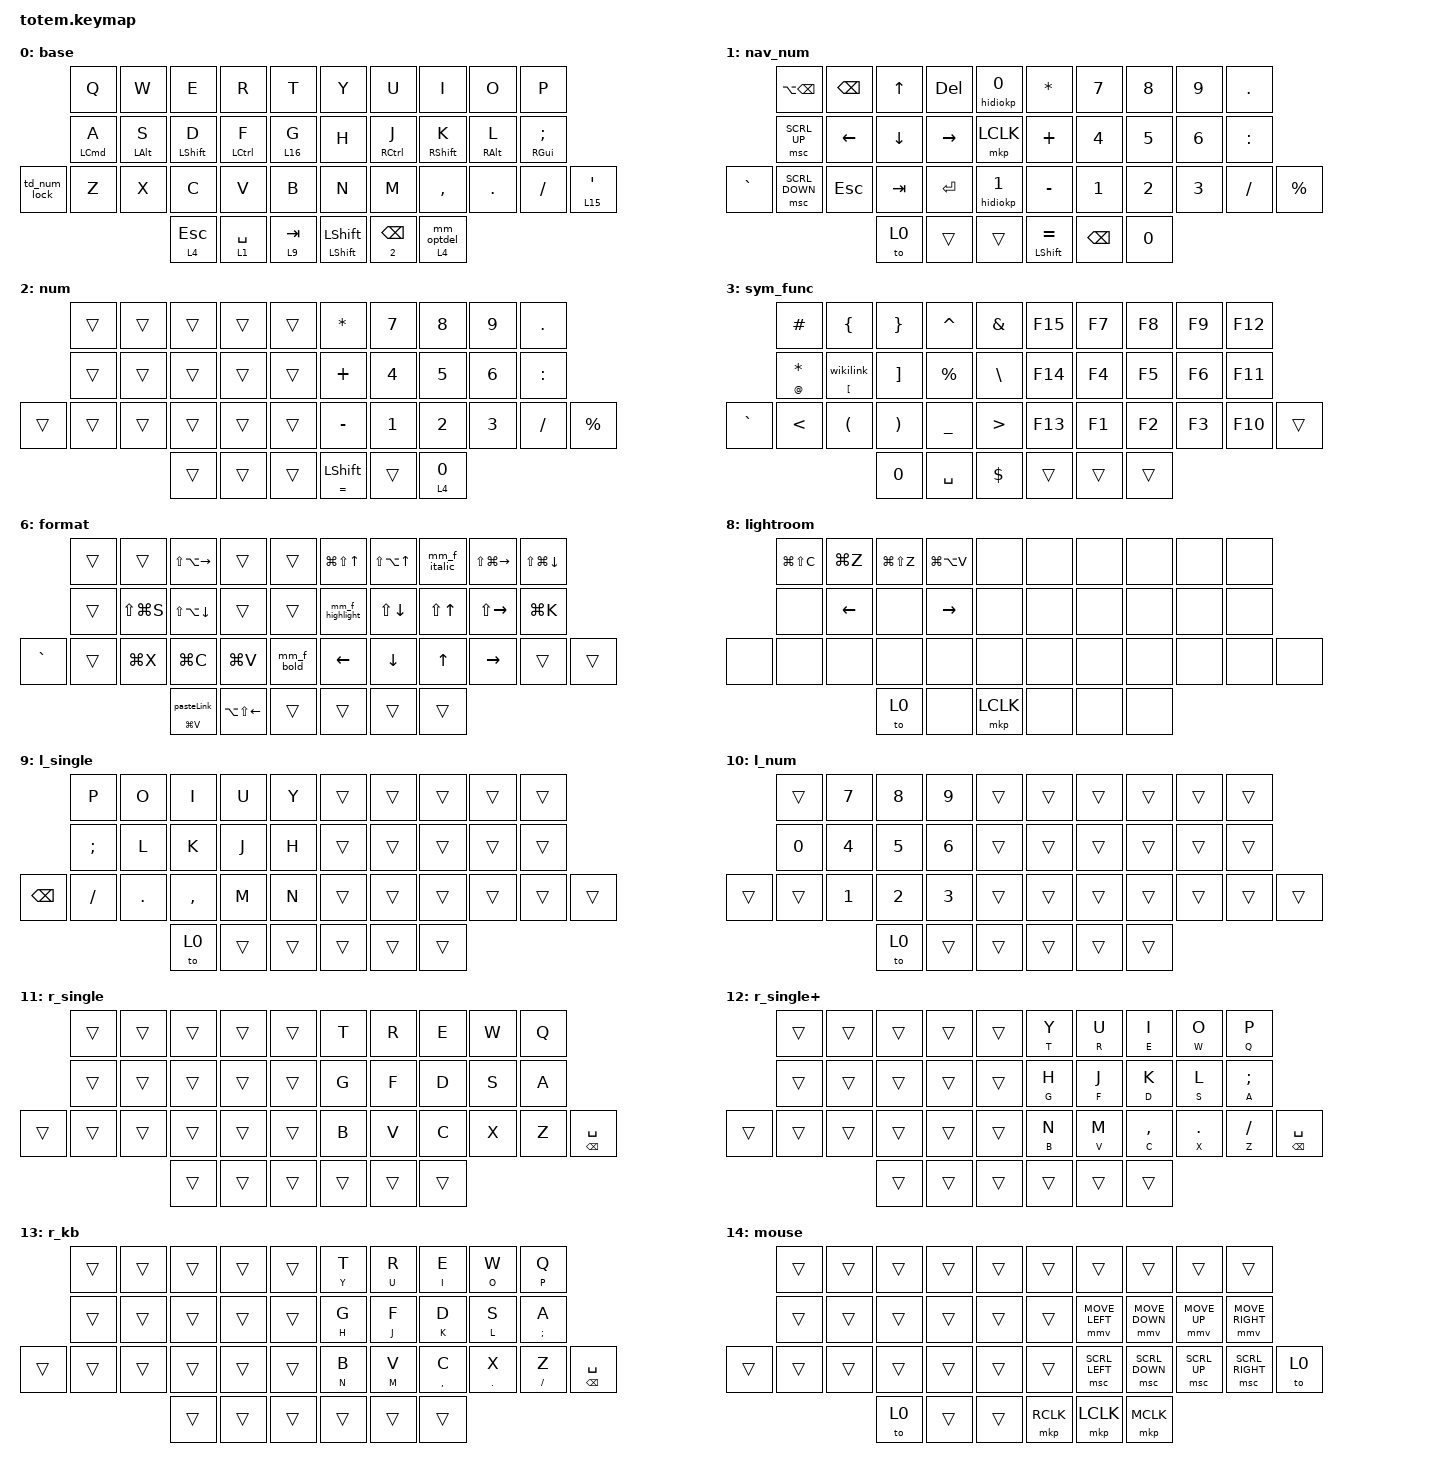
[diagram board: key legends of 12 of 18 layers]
//
//                                                        ▀▀▀▀▀     ▀▀▀▀▀          ▀▀█▀▀
//                                                        ▄▀▀▀▄  ▄  ▄▀▀▀▄  ▄  ▄▀▀▀▄  █  ▄▀▀▀▄
//                                                        █   █  █  █   █  █  █   █  █  █   █
//                                                         ▀▀▀   █   ▀▀▀   █   ▀▀▀   ▀   ▀▀▀
//                                                               █      ▄▄▄█▄▄▄    █   █  
//                                                               ▀      █  █  █     █▄█
//                                                             ▀▀▀▀▀    █  █  █      ▀
//                                                                      ▀  ▀  ▀
//
// ▄▄▄▄▄▄▄▄▄▄▄▄▄▄▄▄▄▄▄▄▄▄▄▄▄▄▄▄▄▄▄▄▄▄▄▄▄▄▄▄▄▄▄▄▄▄▄▄▄▄▄▄▄▄▄▄▄▄▄▄▄▄▄▄▄▄▄▄▄▄▄▄▄▄▄▄▄▄▄▄▄▄▄▄▄▄▄▄▄▄▄▄▄▄▄▄▄▄▄▄▄▄▄▄▄▄▄▄▄▄▄▄▄▄▄▄▄▄▄▄▄▄▄▄▄▄▄▄▄▄▄▄▄▄▄▄▄▄▄▄▄▄▄▄▄▄▄▄▄

#include <behaviors/num_word.dtsi>
#include <behaviors.dtsi>
#include <dt-bindings/zmk/bt.h>
#include <dt-bindings/zmk/keys.h>
#include <dt-bindings/zmk/pointing.h>

#define NUM 2
#define HID_IO_USAGE_FWD_TO_JOYSTICK 2

/ {
    /* Setup input-processor to intecept input and forward to new usage page  */

    zip_fwd_to_hid_io: zip_forward_fwd_to_hid_io {
        compatible = "zmk,input-processor-fwd-to-hid-io";
        #input-processor-cells = <0>;
        usage = <HID_IO_USAGE_FWD_TO_JOYSTICK>;
    };

    /* Setup joystick key press behavior and listener */
    /* listener shall forward to JOYSTICK usage page if CONFIG_ZMK_HID_IO_JOYSTICK is enabled */

    hidiokp: hid_io_key_press {
        compatible = "zmk,behavior-hid-io-key-press";
        #binding-cells = <1>;
    };

    hidiokp_ibl {
        compatible = "zmk,input-listener";
        device = <&hidiokp>;
        input-processors = <&zip_fwd_to_hid_io>;
    };

    combos {
        compatible = "zmk,combos";

        l-undo {
            bindings = <&kp LG(Z)>;
            key-positions = <12 23>;
            layers = <0 14>;
            timeout-ms = <25>;
            require-prior-idle-ms = <100>;
        };

        l-redo {
            bindings = <&kp LG(LS(Z))>;
            key-positions = <11 22>;
            layers = <0 14>;
            timeout-ms = <25>;
            require-prior-idle-ms = <100>;
        };

        l-paste {
            bindings = <&kp LG(V)>;
            key-positions = <23 24>;
            layers = <0 14>;
            timeout-ms = <22>;
            require-prior-idle-ms = <150>;
        };

        l-copy {
            bindings = <&kp LG(C)>;
            key-positions = <23 22>;
            layers = <0 14>;
            timeout-ms = <22>;
            require-prior-idle-ms = <150>;
        };

        l-shift1 {
            bindings = <&sts LSHIFT>;
            key-positions = <24 25>;
            layers = <0 1 9 10>;
            timeout-ms = <18>;
            require-prior-idle-ms = <150>;
        };

        l-cut {
            bindings = <&kp LG(X)>;
            key-positions = <22 24>;
            layers = <0 14>;
            timeout-ms = <22>;
            require-prior-idle-ms = <150>;
        };

        l_emdash {
            bindings = <&kp LA(LS(MINUS))>;
            key-positions = <13 22>;
            layers = <0>;
            timeout-ms = <25>;
            require-prior-idle-ms = <150>;
        };

        l-escape {
            bindings = <&kp ESC>;
            key-positions = <1 2>;
            layers = <0>;
            timeout-ms = <22>;
            require-prior-idle-ms = <150>;
        };

        r-enter {
            bindings = <&kp ENTER>;
            key-positions = <7 6>;
            timeout-ms = <25>;
            require-prior-idle-ms = <100>;
        };

        l-selectAll {
            bindings = <&kp LG(A)>;
            key-positions = <10 0>;
            timeout-ms = <25>;
            require-prior-idle-ms = <150>;
            layers = <0>;
        };

        r-zoomIn {
            bindings = <&kp LG(EQUAL)>;
            key-positions = <9 19>;
            timeout-ms = <30>;
            require-prior-idle-ms = <50>;
            layers = <0>;
        };

        r-zoomOut {
            bindings = <&kp LG(MINUS)>;
            key-positions = <30 19>;
            timeout-ms = <30>;
            require-prior-idle-ms = <50>;
            layers = <0>;
        };

        l-raycast {
            bindings = <&kp LG(LS(LA(LC(SPACE))))>;
            key-positions = <3 13>;
            timeout-ms = <30>;
            require-prior-idle-ms = <50>;
            layers = <0>;
        };

        l-enter {
            bindings = <&kp ENTER>;
            key-positions = <2 3>;
            timeout-ms = <22>;
            require-prior-idle-ms = <150>;
            layers = <0 14>;
        };

        r-mouse {
            bindings = <&tog 14>;
            key-positions = <7 8>;
            timeout-ms = <12>;
            require-prior-idle-ms = <150>;
            layers = <0>;
        };

        l-play_pause {
            bindings = <&kp C_PLAY_PAUSE>;
            key-positions = <13 33>;
            timeout-ms = <30>;
            require-prior-idle-ms = <50>;
            layers = <0 14>;
        };

        f_bold {
            bindings = <&kp LG(B)>;
            key-positions = <13 25>;
            timeout-ms = <22>;
            require-prior-idle-ms = <150>;
            layers = <0>;
        };

        f_italic {
            bindings = <&kp LG(I)>;
            key-positions = <13 7>;
            timeout-ms = <28>;
            require-prior-idle-ms = <150>;
            layers = <0>;
        };

        r_dash {
            bindings = <&kp MINUS>;
            key-positions = <13 27>;
            timeout-ms = <50>;
            require-prior-idle-ms = <50>;
            layers = <0>;
        };

        f_highlight {
            bindings = <&kp LG(LS(H))>;
            key-positions = <13 15>;
            timeout-ms = <28>;
            require-prior-idle-ms = <150>;
            layers = <0>;
        };

        l_dash {
            bindings = <&kp MINUS>;
            key-positions = <13 23>;
            timeout-ms = <25>;
            require-prior-idle-ms = <150>;
            layers = <0>;
        };

        r-spotlight {
            bindings = <&kp LG(SPACE)>;
            key-positions = <6 16>;
            timeout-ms = <30>;
            require-prior-idle-ms = <50>;
            layers = <0>;
        };

        r-playPause {
            bindings = <&kp C_PLAY_PAUSE>;
            key-positions = <16 36>;
            timeout-ms = <30>;
            require-prior-idle-ms = <50>;
            layers = <0>;
        };

        r-back {
            bindings = <&kp LG(LBKT)>;
            key-positions = <15 37>;
            timeout-ms = <30>;
            require-prior-idle-ms = <50>;
            layers = <0>;
        };

        r-prevTab {
            bindings = <&kp LC(LS(TAB))>;
            key-positions = <37 16>;
            timeout-ms = <30>;
            require-prior-idle-ms = <50>;
            layers = <0>;
        };

        r-nextTab {
            bindings = <&kp LC(TAB)>;
            key-positions = <37 17>;
            timeout-ms = <30>;
            require-prior-idle-ms = <50>;
            layers = <0>;
        };

        r-forward {
            bindings = <&kp LG(RBKT)>;
            key-positions = <37 18>;
            timeout-ms = <30>;
            require-prior-idle-ms = <50>;
            layers = <0>;
        };

        r-close {
            bindings = <&kp LG(W)>;
            key-positions = <37 19>;
            timeout-ms = <30>;
            require-prior-idle-ms = <50>;
            layers = <0>;
        };

        r-escape {
            bindings = <&kp ESC>;
            key-positions = <28 27>;
            timeout-ms = <22>;
            require-prior-idle-ms = <150>;
            layers = <0>;
        };

        l-back {
            bindings = <&kp LG(LBKT)>;
            key-positions = <32 14>;
            timeout-ms = <30>;
            require-prior-idle-ms = <50>;
            layers = <0>;
        };

        l-prevTab {
            bindings = <&kp LC(LS(TAB))>;
            key-positions = <13 32>;
            timeout-ms = <30>;
            require-prior-idle-ms = <50>;
            layers = <0>;
        };

        l-nextTab {
            bindings = <&kp LC(TAB)>;
            key-positions = <12 32>;
            timeout-ms = <30>;
            require-prior-idle-ms = <50>;
            layers = <0>;
        };

        l-forward {
            bindings = <&kp LG(RBKT)>;
            key-positions = <11 32>;
            timeout-ms = <30>;
            require-prior-idle-ms = <50>;
            layers = <0>;
        };

        l-close {
            bindings = <&kp LG(W)>;
            key-positions = <10 32>;
            timeout-ms = <30>;
            require-prior-idle-ms = <50>;
            layers = <0>;
        };

        r-minimize {
            bindings = <&kp LG(M)>;
            key-positions = <27 37>;
            timeout-ms = <30>;
            require-prior-idle-ms = <50>;
            layers = <0>;
        };

        l-device {
            bindings = <&mo 17>;
            key-positions = <14 33>;
            timeout-ms = <30>;
            require-prior-idle-ms = <50>;
            layers = <0>;
        };

        l-num_word {
            bindings = <&num_word NUM>;
            key-positions = <24 33>;
            timeout-ms = <30>;
            require-prior-idle-ms = <50>;
            layers = <0>;
        };

        l-shift2 {
            bindings = <&sts LSHIFT>;
            key-positions = <14 34>;
            timeout-ms = <30>;
            require-prior-idle-ms = <50>;
        };

        r-dollar {
            bindings = <&kp DOLLAR>;
            key-positions = <16 36>;
            layers = <1 2>;
            timeout-ms = <30>;
            require-prior-idle-ms = <50>;
        };

        r-hide {
            bindings = <&kp LG(H)>;
            key-positions = <28 37>;
            timeout-ms = <30>;
            require-prior-idle-ms = <50>;
            layers = <0>;
        };

        l-notif {
            bindings = <&kp LS(LA(LC(LG(N))))>;
            key-positions = <32 25>;
            timeout-ms = <30>;
            require-prior-idle-ms = <50>;
            layers = <0>;
        };

        l-minimize {
            bindings = <&kp LG(M)>;
            key-positions = <24 32>;
            timeout-ms = <30>;
            require-prior-idle-ms = <50>;
            layers = <0>;
        };

        l-hide {
            bindings = <&kp LG(H)>;
            key-positions = <23 32>;
            timeout-ms = <30>;
            require-prior-idle-ms = <50>;
            layers = <0>;
        };

        r-s_enter {
            bindings = <&kp LS(ENTER)>;
            key-positions = <7 5>;
            timeout-ms = <25>;
            require-prior-idle-ms = <100>;
            layers = <0>;
        };

        r-soft_off {
            bindings = <&soft_off>;
            key-positions = <31 37>;
        };
    };

    behaviors {
        lt_ext: lt_ext {
            compatible = "zmk,behavior-hold-tap";
            label = "LT_EXT";
            bindings = <&mo>, <&kp>;

            #binding-cells = <2>;
            flavor = "tap-preferred";
            tapping-term-ms = <300>;
            quick-tap-ms = <200>;
            hold-trigger-key-positions = <33>;
            hold-trigger-on-release;
        };

        ht_thrm: ht_hrm {
            compatible = "zmk,behavior-hold-tap";
            label = "Urod timeless hrm, zmk config.";
            bindings = <&kp>, <&kp>;

            #binding-cells = <2>;
            tapping-term-ms = <350>;
            quick-tap-ms = <200>;
            flavor = "balanced";
            require-prior-idle-ms = <150>;
            hold-trigger-on-release;
        };

        mm_optdel: mm_optdel {
            compatible = "zmk,behavior-mod-morph";
            label = "MM_OPTDEL";
            bindings = <&kp LA(BACKSPACE)>, <&kp LA(DEL)>;

            #binding-cells = <0>;
            mods = <(MOD_LSFT|MOD_RSFT)>;
        };

        ht_optdel: ht_optdel {
            compatible = "zmk,behavior-hold-tap";
            label = "HT_OPTDEL";
            bindings = <&mo>, <&mm_optdel>;

            #binding-cells = <2>;
            flavor = "hold-preferred";
            tapping-term-ms = <200>;
        };

        td_num_lock: td_num_lock {
            compatible = "zmk,behavior-tap-dance";
            label = "TD_NUM_LOCK";
            #binding-cells = <0>;
            bindings = <&ht_num_quick 15 NUM>, <&kp LG(LC(Q))>;
        };

        ht_sts_capsword: ht_sts_capsword {
            compatible = "zmk,behavior-hold-tap";
            label = "HT_STS_CAPSWORD";
            bindings = <&mm_sts_r_singleplus>, <&mm_sts_outer_capsword>;

            #binding-cells = <2>;
            tapping-term-ms = <200>;
        };

        sts: sts {
            compatible = "zmk,behavior-sticky-key";
            label = "STS";
            bindings = <&kp>;
            #binding-cells = <1>;
            quick-release;
            release-after-ms = <2000>;
            ignore-modifiers;
        };

        ht_num_quick: ht_num_quick {
            compatible = "zmk,behavior-hold-tap";
            label = "HT_NUM_QUICK";
            #binding-cells = <2>;
            tapping-term-ms = <200>;
            bindings = <&mo>, <&num_word>;
        };

        mm_sts_capsword: mm_sts_capsword {
            compatible = "zmk,behavior-mod-morph";
            label = "MM_STS_CAPSWORD";
            bindings = <&sts LSHIFT>, <&caps_word>;

            #binding-cells = <0>;
            mods = <(MOD_LSFT)>;
        };

        ht_r_thrm: ht_r_thrm {
            compatible = "zmk,behavior-hold-tap";
            label = "HT_R_THRM";
            bindings = <&kp>, <&kp>;

            #binding-cells = <2>;
            tapping-term-ms = <350>;
            quick-tap-ms = <200>;
            flavor = "balanced";
            require-prior-idle-ms = <170>;
            hold-trigger-on-release;
            hold-trigger-key-positions = <35 36 37 32 33 34 2 3 4 13 12 13 23 14 14 25 24 22 1 11 10 21 0 10 20 1 2 3 4 11 12 13 14 22 23 24 25 0>;
        };

        ht_l_thrm: ht_l_thrm {
            compatible = "zmk,behavior-hold-tap";
            label = "HT_L_THRM";
            bindings = <&kp>, <&kp>;

            #binding-cells = <2>;
            tapping-term-ms = <350>;
            quick-tap-ms = <200>;
            flavor = "balanced";
            require-prior-idle-ms = <170>;
            hold-trigger-on-release;
            hold-trigger-key-positions = <35 36 37 32 33 34 5 15 26 27 16 6 7 17 28 29 18 8 9 19 30 31>;
        };

        ht_sym_func: ht_sym_func {
            compatible = "zmk,behavior-hold-tap";
            label = "HT_SYM_FUNC";
            #binding-cells = <2>;
            tapping-term-ms = <300>;
            quick-tap-ms = <200>;
            bindings = <&mm_r_single>, <&kp>;
        };

        mm_r_single: mm_r_single {
            compatible = "zmk,behavior-mod-morph";
            label = "MM_R_SINGLE";
            bindings = <&mo 3>, <&mo 11>;

            #binding-cells = <0>;
            mods = <(MOD_RCTL)>;
        };

        mm_sts_r_singleplus: mm_sts_r_singleplus {
            compatible = "zmk,behavior-mod-morph";
            label = "MM_STS_R_SINGLEPLUS";
            bindings = <&kp LSHIFT>, <&mo 12>;

            #binding-cells = <0>;
            mods = <(MOD_RCTL)>;
        };

        mm_f_highlight: mm_f_highlight {
            compatible = "zmk,behavior-mod-morph";
            label = "MM_F_HIGHLIGHT";
            bindings = <&kp LS(LEFT)>, <&kp LG(LS(H))>;

            #binding-cells = <0>;
            mods = <(MOD_LSFT)>;
        };

        mm_f_bold: mm_f_bold {
            compatible = "zmk,behavior-mod-morph";
            label = "MM_F_BOLD";
            bindings = <&kp LS(LA(LEFT))>, <&kp LG(B)>;

            #binding-cells = <0>;
            mods = <(MOD_LSFT)>;
        };

        mm_f_italic: mm_f_italic {
            compatible = "zmk,behavior-mod-morph";
            label = "MM_F_ITALIC";
            bindings = <&kp LS(LG(LEFT))>, <&kp LG(I)>;

            #binding-cells = <0>;
            mods = <(MOD_LSFT)>;
        };

        mm_sts_inner: mm_sts_inner {
            compatible = "zmk,behavior-mod-morph";
            label = "MM_STS_INNER";
            bindings = <&sts LSHIFT>, <&kp TAB>;

            #binding-cells = <0>;
            mods = <(MOD_RGUI)>;
            keep-mods = <(MOD_RGUI)>;
        };

        mm_sts_outer_capsword: mm_sts_outer_capsword {
            compatible = "zmk,behavior-mod-morph";
            label = "MM_STS_OUTER_CAPSWORD";
            bindings = <&mm_sts_inner>, <&caps_word>;

            #binding-cells = <0>;
            mods = <(MOD_LSFT)>;
        };

        wikilink_bracket: wikilink_bracket {
            compatible = "zmk,behavior-hold-tap";
            label = "WIKILINK_BRACKET";
            bindings = <&kp>, <&wikilink>;

            #binding-cells = <2>;
            tapping-term-ms = <200>;
        };

        pasteLink_paste: pasteLink_paste {
            compatible = "zmk,behavior-hold-tap";
            label = "PASTELINK_PASTE";
            #binding-cells = <2>;
            tapping-term-ms = <200>;
            bindings = <&kp>, <&pasteLink>;
        };

        num_word: num_word {
            compatible = "zmk,behavior-auto-layer";
            continue-list = <BSPC DEL DOT COMMA PLUS MINUS STAR FSLH EQUAL LSHIFT COLON>;
            ignore-numbers;
        };

        ht_sts_kp: ht_sts_kp {
            compatible = "zmk,behavior-hold-tap";
            label = "HT_STS_KP";
            bindings = <&kp>, <&sts>;

            #binding-cells = <2>;
            tapping-term-ms = <200>;
        };
    };

    macros {
        wikilink: wikilink {
            compatible = "zmk,behavior-macro";
            #binding-cells = <0>;
            bindings = <&kp LBKT &kp LBKT>;
            label = "WIKILINK";
        };

        pasteLink: pasteLink {
            compatible = "zmk,behavior-macro";
            #binding-cells = <0>;
            bindings = <&kp LS(LA(LEFT)) &kp LG(V)>;
            label = "PASTELINK";
        };
    };

    keymap {
        compatible = "zmk,keymap";

        base {
            bindings = <
              &kp Q              &kp W              &kp E                &kp R               &kp T           &kp Y                           &kp U                &kp I                &kp O              &kp P
              &ht_l_thrm LCMD A  &ht_l_thrm LALT S  &ht_l_thrm LSHIFT D  &ht_l_thrm LCTRL F  &lt_ext 16 G    &kp H                           &ht_r_thrm RCTRL J   &ht_r_thrm RSHIFT K  &ht_r_thrm RALT L  &ht_r_thrm RIGHT_GUI SEMICOLON
&td_num_lock  &kp Z              &kp X              &kp C                &kp V               &kp B           &kp N                           &kp M                &kp COMMA            &kp DOT            &kp FSLH                        &lt_ext 15 APOSTROPHE
                                                    &lt 4 ESCAPE         &lt 1 SPACE         &lt 9 TAB       &ht_sts_capsword LSHIFT LSHIFT  &ht_sym_func 2 BSPC  &ht_optdel 4 0
            >;
        };

        nav_num {
            bindings = <
           &kp LA(BACKSPACE)  &kp BACKSPACE  &kp UP    &kp DELETE  &hidiokp 0    &kp STAR          &kp N7         &kp N8  &kp N9  &kp DOT
           &msc SCRL_UP       &kp LEFT       &kp DOWN  &kp RIGHT   &mkp LCLK     &kp PLUS          &kp N4         &kp N5  &kp N6  &kp COLON
&kp GRAVE  &msc SCRL_DOWN     &kp ESC        &kp TAB   &kp ENTER   &hidiokp 1    &kp MINUS         &kp NUMBER_1   &kp N2  &kp N3  &kp SLASH  &kp PERCENT
                                             &to 0     &trans      &trans        &mt LSHIFT EQUAL  &kp BACKSPACE  &kp N0
            >;
        };

        num {
            bindings = <
        &trans  &trans  &trans  &trans  &trans    &kp STAR                 &kp N7        &kp N8    &kp N9  &kp DOT
        &trans  &trans  &trans  &trans  &trans    &kp PLUS                 &kp N4        &kp N5    &kp N6  &kp COLON
&trans  &trans  &trans  &trans  &trans  &trans    &kp MINUS                &kp NUMBER_1  &kp N2    &kp N3  &kp SLASH  &kp PERCENT
                        &trans  &trans  &trans    &ht_sts_kp EQUAL LSHIFT  &trans        &lt 4 N0
            >;
        };

        sym_func {
            bindings = <
           &kp HASH     &kp LEFT_BRACE            &kp RIGHT_BRACE        &kp CARET    &kp AMPERSAND    &kp F15  &kp F7  &kp F8  &kp F9  &kp F12
           &mt AT STAR  &wikilink_bracket LBKT 0  &kp RBKT               &kp PERCENT  &kp BACKSLASH    &kp F14  &kp F4  &kp F5  &kp F6  &kp F11
&kp GRAVE  &kp LT       &kp LEFT_PARENTHESIS      &kp RIGHT_PARENTHESIS  &kp UNDER    &kp GT           &kp F13  &kp F1  &kp F2  &kp F3  &kp F10  &trans
                                                  &kp N0                 &kp SPACE    &kp DOLLAR       &trans   &trans  &trans
            >;
        };

        z_hyp {
            bindings = <
               &kp LS(LA(LC(LG(Q))))  &kp BACKSPACE              &kp LA(RIGHT)                               &kp DEL                    &trans                   &kp LG(UP)             &kp LA(UP)                   &kp LG(LEFT)                 &kp LG(RIGHT)  &kp LG(DOWN)
               &kp CAPS               &lt (7) LS(LA(LC(LG(S))))  &kp LA(DOWN)                                &lt (6) LS(LA(LC(LG(F))))  &kp LS(LA(LC(LG(G))))    &kp LEFT               &kp DOWN                     &kp UP                       &kp RIGHT      &kp SPACE
&kp LS(ENTER)  &trans                 &trans                     &mt (LA(LC(LG(LS(N6))))) LS(LA(LC(LG(C))))  &kp LS(LA(LG(LC(V))))      &kp LA(LEFT)             &kp LS(LA(LC(LG(N))))  &mt (LA(LS(LEFT))) LA(BSPC)  &mt (LA(LS(RIGHT))) LA(DEL)  &kp ESC        &tog 4        &kp ENTER
                                                                 &to 0                                       &trans                     &trans                   &kp SPACE              &trans                       &trans
            >;
        };

        z_hyp_num {
            bindings = <
        &trans  &trans  &trans  &trans  &trans    &trans  &kp LS(LA(LC(LG(N7))))  &kp LS(LA(LC(LG(N8))))  &kp LS(LA(LC(LG(N9))))  &trans
        &trans  &trans  &trans  &trans  &trans    &trans  &kp LS(LA(LC(LG(N4))))  &kp LS(LA(LC(LG(N5))))  &kp LS(LA(LC(LG(N6))))  &trans
&trans  &trans  &trans  &trans  &trans  &trans    &trans  &kp LS(LA(LC(LG(N1))))  &kp LS(LA(LC(LG(N2))))  &kp LS(LA(LC(LG(N3))))  &tog 5  &trans
                        &to 0   &trans  &trans    &trans  &trans                  &trans
            >;
        };

        format {
            bindings = <
           &trans  &trans         &kp LS(LA(RIGHT))         &trans            &trans        &kp LG(LS(UP))   &kp LS(LA(UP))  &mm_f_italic  &kp LS(LG(RIGHT))  &kp LS(LG(DOWN))
           &trans  &kp LS(LG(S))  &kp LS(LA(DOWN))          &trans            &trans        &mm_f_highlight  &kp LS(DOWN)    &kp LS(UP)    &kp LS(RIGHT)      &kp LG(K)
&kp GRAVE  &trans  &kp LG(X)      &kp LG(C)                 &kp LG(V)         &mm_f_bold    &kp LEFT         &kp DOWN        &kp UP        &kp RIGHT          &trans            &trans
                                  &pasteLink_paste LG(V) 0  &kp LA(LS(LEFT))  &trans        &trans           &trans          &trans
            >;
        };

        system {
            bindings = <
        &trans  &trans  &trans  &trans                 &trans                   &trans                &trans           &trans       &trans                 &trans
        &trans  &trans  &trans  &kp LS(LA(LG(LC(F))))  &kp LS(LC(LA(LG(G))))    &kp LG(LEFT_BRACKET)  &kp LC(LS(TAB))  &kp LC(TAB)  &kp LG(RIGHT_BRACKET)  &kp LG(W)
&trans  &trans  &trans  &trans  &trans                 &trans                   &trans                &trans           &trans       &trans                 &trans     &trans
                        &trans  &trans                 &trans                   &trans                &trans           &trans
            >;
        };

        lightroom {
            bindings = <
       &kp LG(LS(C))  &kp LG(Z)  &kp LG(LS(Z))  &kp LG(LA(V))  &none        &none  &none  &none  &none  &none
       &none          &kp LEFT   &none          &kp RIGHT      &none        &none  &none  &none  &none  &none
&none  &none          &none      &none          &none          &none        &none  &none  &none  &none  &none  &none
                                 &to 0          &none          &mkp LCLK    &none  &none  &none
            >;
        };

        l_single {
            bindings = <
               &kp P          &kp O       &kp I      &kp U   &kp Y     &trans  &trans  &trans  &trans  &trans
               &kp SEMICOLON  &kp L       &kp K      &kp J   &kp H     &trans  &trans  &trans  &trans  &trans
&kp BACKSPACE  &kp SLASH      &kp PERIOD  &kp COMMA  &kp M   &kp N     &trans  &trans  &trans  &trans  &trans  &trans
                                          &to 0      &trans  &trans    &trans  &trans  &trans
            >;
        };

        l_num {
            bindings = <
        &trans  &kp N7  &kp N8  &kp N9  &trans    &trans  &trans  &trans  &trans  &trans
        &kp N0  &kp N4  &kp N5  &kp N6  &trans    &trans  &trans  &trans  &trans  &trans
&trans  &trans  &kp N1  &kp N2  &kp N3  &trans    &trans  &trans  &trans  &trans  &trans  &trans
                        &to 0   &trans  &trans    &trans  &trans  &trans
            >;
        };

        r_single {
            bindings = <
        &trans  &trans  &trans  &trans  &trans    &kp T   &kp R   &kp E   &kp W  &kp Q
        &trans  &trans  &trans  &trans  &trans    &kp G   &kp F   &kp D   &kp S  &kp A
&trans  &trans  &trans  &trans  &trans  &trans    &kp B   &kp V   &kp C   &kp X  &kp Z  &mt BSPC SPACE
                        &trans  &trans  &trans    &trans  &trans  &trans
            >;
        };

        r_single+ {
            bindings = <
        &trans  &trans  &trans  &trans  &trans    &mt T Y  &mt R U  &mt E I      &mt W O       &mt Q P
        &trans  &trans  &trans  &trans  &trans    &mt G H  &mt F J  &mt D K      &mt S L       &mt A SEMICOLON
&trans  &trans  &trans  &trans  &trans  &trans    &mt B N  &mt V M  &mt C COMMA  &mt X PERIOD  &mt Z SLASH      &mt BSPC SPACE
                        &trans  &trans  &trans    &trans   &trans   &trans
            >;
        };

        r_kb {
            bindings = <
        &trans  &trans  &trans  &trans  &trans    &mt Y T  &mt U R  &mt I E      &mt O W    &mt P Q
        &trans  &trans  &trans  &trans  &trans    &mt H G  &mt J F  &mt K D      &mt L S    &mt SEMI A
&trans  &trans  &trans  &trans  &trans  &trans    &mt N B  &mt M V  &mt COMMA C  &mt DOT X  &mt FSLH Z  &mt BSPC SPACE
                        &trans  &trans  &trans    &trans   &trans   &trans
            >;
        };

        mouse {
            bindings = <
        &trans  &trans  &trans  &trans  &trans    &trans     &trans          &trans          &trans        &trans
        &trans  &trans  &trans  &trans  &trans    &trans     &mmv MOVE_LEFT  &mmv MOVE_DOWN  &mmv MOVE_UP  &mmv MOVE_RIGHT
&trans  &trans  &trans  &trans  &trans  &trans    &trans     &msc SCRL_LEFT  &msc SCRL_DOWN  &msc SCRL_UP  &msc SCRL_RIGHT  &to 0
                        &to 0   &trans  &trans    &mkp RCLK  &mkp LCLK       &mkp MCLK
            >;
        };

        quick {
            bindings = <
        &kp CARET                     &kp LG(LS(N2))         &kp LG(LS(N3))         &kp LG(LS(N4))        &kp LG(LS(N5))    &kp LG(LS(N5))  &kp LG(LS(N4))          &kp LG(LS(N3))          &kp LG(LS(N2))          &trans
        &kp LA(LS(C_BRIGHTNESS_DEC))  &kp LS(LA(C_BRI_UP))   &kp LS(LA(C_VOL_DN))   &kp LS(LA(C_VOL_UP))  &kp C_MUTE        &kp C_MUTE      &kp LS(LA(LC(LG(N4))))  &kp LG(LS(LA(LC(N3))))  &kp LG(LA(LC(LS(N2))))  &kp LC(LS(LA(LG(N1))))
&trans  &kp LS(LA(LC(LG(M))))         &kp LS(LA(LC(LG(F))))  &kp LS(LA(LC(LG(G))))  &trans                &trans            &trans          &trans                  &trans                  &trans                  &trans                  &trans
                                                             &trans                 &trans                &trans            &trans          &trans                  &trans
            >;
        };

        macro {
            bindings = <
        &trans  &trans  &to 8   &trans  &trans    &trans  &trans  &trans  &trans  &trans
        &trans  &to 9   &trans  &trans  &trans    &trans  &trans  &trans  &to 8   &trans
&trans  &trans  &trans  &trans  &trans  &trans    &to 1   &trans  &trans  &trans  &trans  &trans
                        &trans  &mo 17  &trans    &trans  &trans  &trans
            >;
        };

        device {
            bindings = <
       &none  &none         &kp C_MUTE    &kp C_PLAY_PAUSE  &none    &bt BT_SEL 0  &bt BT_SEL 1  &bt BT_SEL 2  &bt BT_SEL 3  &bt BT_SEL 4
       &none  &kp C_BRI_UP  &kp C_VOL_UP  &kp C_NEXT        &none    &none         &none         &none         &none         &none
&none  &none  &kp C_BRI_DN  &kp C_VOL_DN  &kp C_PREV        &none    &none         &none         &none         &none         &none         &bt BT_CLR
                            &none         &none             &none    &none         &none         &none
            >;
        };
    };

    conditional_layers {
        compatible = "zmk,conditional-layers";

        z_hyp_num {
            if-layers = <1 4>;
            then-layer = <5>;
        };

        l_num {
            if-layers = <1 9>;
            then-layer = <10>;
        };
    };
};
